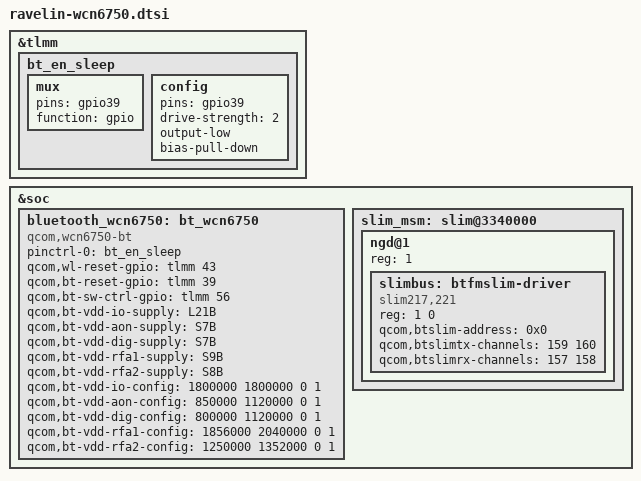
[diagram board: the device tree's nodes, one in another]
// SPDX-License-Identifier: BSD-3-Clause

/*
 * Copyright (c) Qualcomm Technologies, Inc. and/or its subsidiaries.
 */

#include <dt-bindings/interconnect/qcom,ravelin.h>
#include <dt-bindings/clock/qcom,rpmh.h>

&tlmm {
	bt_en_sleep: bt_en_sleep {
	mux {
		pins = "gpio39";
		function = "gpio";
	};

	config {
		pins = "gpio39";
		drive-strength = <2>;
		output-low;
		bias-pull-down;
		};
	};
};

&soc {
	bluetooth_wcn6750: bt_wcn6750 {
		status =  "ok";
		compatible = "qcom,wcn6750-bt";
		pinctrl-names = "default";
		pinctrl-0 = <&bt_en_sleep>;
		qcom,wl-reset-gpio = <&tlmm 43 0>; /* WL_CTRL */
		qcom,bt-reset-gpio = <&tlmm 39 0>; /* BT_EN */
		qcom,bt-sw-ctrl-gpio = <&tlmm 56 0>; /* SW_CTRL */

		qcom,bt-vdd-io-supply = <&L21B>;  /* IO */
		qcom,bt-vdd-aon-supply = <&S7B>;
		qcom,bt-vdd-dig-supply = <&S7B>; /* BT_CX_MX */
		qcom,bt-vdd-rfa1-supply = <&S9B>; /* RFA 1p7 */
		qcom,bt-vdd-rfa2-supply = <&S8B>; /* RFA 1p2 */

		/* Max Voltages are derived from the buck Max Voltage */
		qcom,bt-vdd-io-config = <1800000 1800000 0 1>;
		qcom,bt-vdd-aon-config = <850000 1120000 0 1>;
		qcom,bt-vdd-dig-config = <800000 1120000 0 1>;
		qcom,bt-vdd-rfa1-config = <1856000 2040000 0 1>;
		qcom,bt-vdd-rfa2-config = <1250000 1352000 0 1>;
	};

        slim_msm: slim@3340000 {
                status = "ok";
                ngd@1 {
                        reg = <1>;
                        #address-cells = <1>;
                        #size-cells = <1>;

                        // slimbus child nodes
                        slimbus: btfmslim-driver {
                                compatible = "slim217,221";
                                reg = <1 0>;
                                qcom,btslim-address = <0x0>; /* BT SLIM EP address */
                                qcom,btslimtx-channels = <159 160>;
                                qcom,btslimrx-channels = <157 158>;
                        };
                };
        };

};


